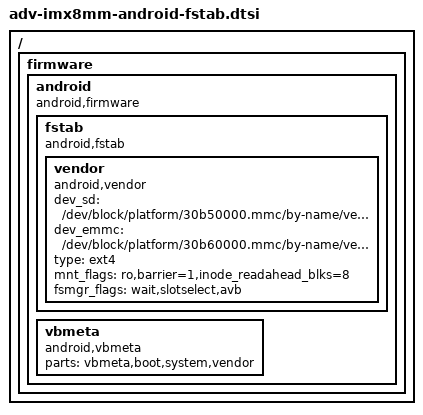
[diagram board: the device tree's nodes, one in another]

/ {
        firmware {
                android {
                        compatible = "android,firmware";
                        fstab {
                                compatible = "android,fstab";
                                vendor {
                                        compatible = "android,vendor";
                                        /* sd card node which used if androidboot.storage_type=sd */
                                        dev_sd = "/dev/block/platform/30b50000.mmc/by-name/vendor";
                                        /* emmc node which used if androidboot.storage_type=emmc */
                                        dev_emmc = "/dev/block/platform/30b60000.mmc/by-name/vendor";
                                        type = "ext4";
                                        mnt_flags = "ro,barrier=1,inode_readahead_blks=8";
                                        fsmgr_flags = "wait,slotselect,avb";
                                };
                        };
                        vbmeta {
                                /*we need use FirstStageMountVBootV2 if we enable avb*/
                                compatible = "android,vbmeta";
                                /*parts means the partition witch can be mount in first stage*/
                                parts = "vbmeta,boot,system,vendor";
                        };
                };
        };
};


